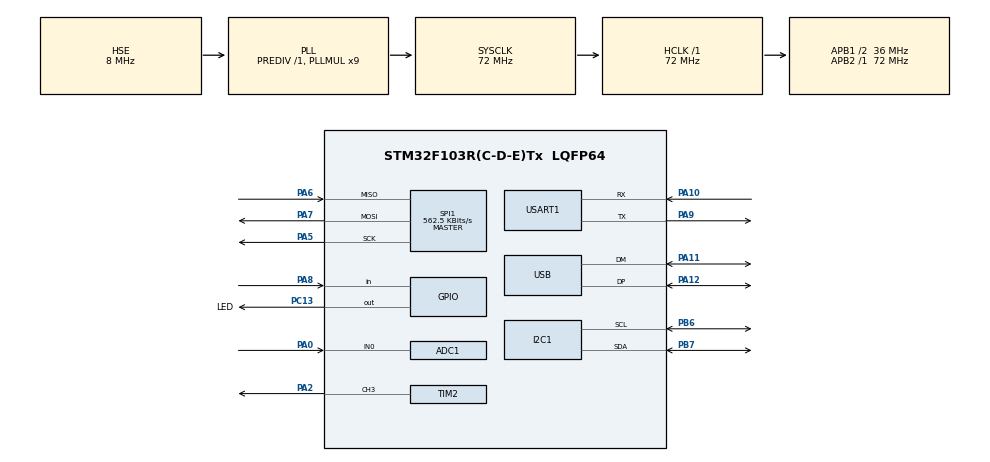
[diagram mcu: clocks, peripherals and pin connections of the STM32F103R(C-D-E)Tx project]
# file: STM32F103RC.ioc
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ADC1.Channel-0\#ChannelRegularConversion=ADC_CHANNEL_0
ADC1.NbrOfConversionFlag=1
ADC1.Rank-0\#ChannelRegularConversion=1
ADC1.SamplingTime-0\#ChannelRegularConversion=ADC_SAMPLETIME_13CYCLES_5
ADC1.master=1
Dma.Request0=USART1_RX
Dma.Request1=USART1_TX
Dma.USART1_RX.0.Direction=DMA_PERIPH_TO_MEMORY
Dma.USART1_RX.0.Instance=DMA1_Channel5
Dma.USART1_RX.0.MemDataAlignment=DMA_MDATAALIGN_BYTE
Dma.USART1_RX.0.MemInc=DMA_MINC_ENABLE
Dma.USART1_RX.0.Mode=DMA_NORMAL
Dma.USART1_RX.0.PeriphDataAlignment=DMA_PDATAALIGN_BYTE
Dma.USART1_RX.0.PeriphInc=DMA_PINC_DISABLE
Dma.USART1_RX.0.Priority=DMA_PRIORITY_LOW
Dma.USART1_TX.1.Direction=DMA_MEMORY_TO_PERIPH
Dma.USART1_TX.1.Instance=DMA1_Channel4
Dma.USART1_TX.1.MemDataAlignment=DMA_MDATAALIGN_BYTE
Dma.USART1_TX.1.MemInc=DMA_MINC_ENABLE
Dma.USART1_TX.1.Mode=DMA_NORMAL
Dma.USART1_TX.1.PeriphDataAlignment=DMA_PDATAALIGN_BYTE
Dma.USART1_TX.1.PeriphInc=DMA_PINC_DISABLE
Dma.USART1_TX.1.Priority=DMA_PRIORITY_LOW
FREERTOS.INCLUDE_vTaskDelayUntil=1
FREERTOS.Tasks01=defaultTask,0,512,StartDefaultTask,Default,NULL,Dynamic,NULL,NULL
FREERTOS.configTOTAL_HEAP_SIZE=8000
FREERTOS.configUSE_COUNTING_SEMAPHORES=1
FREERTOS.configUSE_RECURSIVE_MUTEXES=1
Mcu.Family=STM32F1
Mcu.Name=STM32F103R(C-D-E)Tx
Mcu.Package=LQFP64
NVIC.DMA1_Channel4_IRQn=true\:5\:0\:false\:false\:true\:true\:false\:true\:true
NVIC.DMA1_Channel5_IRQn=true\:5\:0\:false\:false\:true\:true\:false\:true\:true
NVIC.PriorityGroup=NVIC_PRIORITYGROUP_4
NVIC.TIM3_IRQn=true\:0\:0\:false\:false\:true\:false\:false\:true\:true
NVIC.TimeBase=TIM3_IRQn
NVIC.TimeBaseIP=TIM3
NVIC.USART1_IRQn=true\:5\:0\:false\:false\:true\:true\:true\:true\:true
NVIC.USB_HP_CAN1_TX_IRQn=true\:5\:0\:false\:false\:true\:true\:true\:true\:true
NVIC.USB_LP_CAN1_RX0_IRQn=true\:5\:0\:false\:false\:true\:true\:true\:true\:true
PA0-WKUP.Signal=ADCx_IN0
PA10.Mode=Asynchronous
PA10.Signal=USART1_RX
PA11.Mode=Device
PA11.Signal=USB_DM
PA12.Mode=Device
PA12.Signal=USB_DP
PA13.Mode=Serial_Wire
PA13.Signal=SYS_JTMS-SWDIO
PA14.Mode=Serial_Wire
PA14.Signal=SYS_JTCK-SWCLK
PA2.Signal=S_TIM2_CH3
PA5.Mode=Full_Duplex_Master
PA5.Signal=SPI1_SCK
PA6.Mode=Full_Duplex_Master
PA6.Signal=SPI1_MISO
PA7.Mode=Full_Duplex_Master
PA7.Signal=SPI1_MOSI
PA8.GPIO_PuPd=GPIO_PULLUP
PA8.Signal=GPIO_Input
PA9.Mode=Asynchronous
PA9.Signal=USART1_TX
PB6.Mode=I2C
PB6.Signal=I2C1_SCL
PB7.Mode=I2C
PB7.Signal=I2C1_SDA
PC13-TAMPER-RTC.GPIO_Label=LED
PC13-TAMPER-RTC.Signal=GPIO_Output
PD0-OSC_IN.Mode=HSE-External-Oscillator
PD0-OSC_IN.Signal=RCC_OSC_IN
PD1-OSC_OUT.Mode=HSE-External-Oscillator
PD1-OSC_OUT.Signal=RCC_OSC_OUT
ProjectManager.HeapSize=0x200
ProjectManager.StackSize=0x400
ProjectManager.TargetToolchain=CMake
RCC.ADCPresc=RCC_ADCPCLK2_DIV6
RCC.AHBFreq_Value=72000000
RCC.APB1CLKDivider=RCC_HCLK_DIV2
RCC.APB1Freq_Value=36000000
RCC.APB1TimFreq_Value=72000000
RCC.APB2Freq_Value=72000000
RCC.APB2TimFreq_Value=72000000
RCC.HCLKFreq_Value=72000000
RCC.PLLMUL=RCC_PLL_MUL9
RCC.PLLSourceVirtual=RCC_PLLSOURCE_HSE
RCC.SYSCLKFreq_VALUE=72000000
RCC.SYSCLKSource=RCC_SYSCLKSOURCE_PLLCLK
RCC.USBFreq_Value=48000000
RCC.USBPrescaler=RCC_USBCLKSOURCE_PLL_DIV1_5
SH.ADCx_IN0.0=ADC1_IN0,IN0
SH.S_TIM2_CH3.0=TIM2_CH3,PWM Generation3 CH3
SPI1.BaudRatePrescaler=SPI_BAUDRATEPRESCALER_128
SPI1.CalculateBaudRate=562.5 KBits/s
SPI1.Direction=SPI_DIRECTION_2LINES
SPI1.Mode=SPI_MODE_MASTER
SPI1.VirtualType=VM_MASTER
TIM2.Channel-PWM\ Generation3\ CH3=TIM_CHANNEL_3
USART1.VirtualMode=VM_ASYNC
VP_FREERTOS_VS_CMSIS_V1.Mode=CMSIS_V1
VP_SYS_VS_tim3.Mode=TIM3
board=custom

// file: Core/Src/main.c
/* USER CODE BEGIN Header */
/**
  ******************************************************************************
  * @file           : main.c
  * @brief          : Main program body
  ******************************************************************************
  * @attention
  *
  * Copyright (c) 2025 STMicroelectronics.
  * All rights reserved.
  *
  * This software is licensed under terms that can be found in the LICENSE file
  * in the root directory of this software component.
  * If no LICENSE file comes with this software, it is provided AS-IS.
  *
  ******************************************************************************
  */
/* USER CODE END Header */
#include "main.h"
#include "cmsis_os.h"

ADC_HandleTypeDef hadc1;

I2C_HandleTypeDef hi2c1;

SPI_HandleTypeDef hspi1;

TIM_HandleTypeDef htim2;

UART_HandleTypeDef huart1;
DMA_HandleTypeDef hdma_usart1_rx;
DMA_HandleTypeDef hdma_usart1_tx;

PCD_HandleTypeDef hpcd_USB_FS;

osThreadId defaultTaskHandle;

void SystemClock_Config(void);
static void MX_GPIO_Init(void);
static void MX_DMA_Init(void);
static void MX_USART1_UART_Init(void);
static void MX_ADC1_Init(void);
static void MX_I2C1_Init(void);
static void MX_SPI1_Init(void);
static void MX_TIM2_Init(void);
static void MX_USB_PCD_Init(void);
void StartDefaultTask(void const * argument);

/* USER CODE BEGIN 0 */
#include "app_main.h"
/* USER CODE END 0 */

int main(void)
{

  /* MCU Configuration--------------------------------------------------------*/

  /* Reset of all peripherals, Initializes the Flash interface and the Systick. */
  HAL_Init();

  /* Configure the system clock */
  SystemClock_Config();

  /* Initialize all configured peripherals */
  MX_GPIO_Init();
  MX_DMA_Init();
  MX_USART1_UART_Init();
  MX_ADC1_Init();
  MX_I2C1_Init();
  MX_SPI1_Init();
  MX_TIM2_Init();
  MX_USB_PCD_Init();

  /* Create the thread(s) */
  /* definition and creation of defaultTask */
  osThreadDef(defaultTask, StartDefaultTask, osPriorityNormal, 0, 512);
  defaultTaskHandle = osThreadCreate(osThread(defaultTask), NULL);

  /* Start scheduler */
  osKernelStart();

  /* We should never get here as control is now taken by the scheduler */

  /* Infinite loop */
  while (1)
  {

  }
}

void SystemClock_Config(void)
{
  RCC_OscInitTypeDef RCC_OscInitStruct = {0};
  RCC_ClkInitTypeDef RCC_ClkInitStruct = {0};
  RCC_PeriphCLKInitTypeDef PeriphClkInit = {0};

  /** Initializes the RCC Oscillators according to the specified parameters
  * in the RCC_OscInitTypeDef structure.
  */
  RCC_OscInitStruct.OscillatorType = RCC_OSCILLATORTYPE_HSE;
  RCC_OscInitStruct.HSEState = RCC_HSE_ON;
  RCC_OscInitStruct.HSEPredivValue = RCC_HSE_PREDIV_DIV1;
  RCC_OscInitStruct.HSIState = RCC_HSI_ON;
  RCC_OscInitStruct.PLL.PLLState = RCC_PLL_ON;
  RCC_OscInitStruct.PLL.PLLSource = RCC_PLLSOURCE_HSE;
  RCC_OscInitStruct.PLL.PLLMUL = RCC_PLL_MUL9;
  if (HAL_RCC_OscConfig(&RCC_OscInitStruct) != HAL_OK)
  {
    Error_Handler();
  }

  /** Initializes the CPU, AHB and APB buses clocks
  */
  RCC_ClkInitStruct.ClockType = RCC_CLOCKTYPE_HCLK|RCC_CLOCKTYPE_SYSCLK
                              |RCC_CLOCKTYPE_PCLK1|RCC_CLOCKTYPE_PCLK2;
  RCC_ClkInitStruct.SYSCLKSource = RCC_SYSCLKSOURCE_PLLCLK;
  RCC_ClkInitStruct.AHBCLKDivider = RCC_SYSCLK_DIV1;
  RCC_ClkInitStruct.APB1CLKDivider = RCC_HCLK_DIV2;
  RCC_ClkInitStruct.APB2CLKDivider = RCC_HCLK_DIV1;

  if (HAL_RCC_ClockConfig(&RCC_ClkInitStruct, FLASH_LATENCY_2) != HAL_OK)
  {
    Error_Handler();
  }
  PeriphClkInit.PeriphClockSelection = RCC_PERIPHCLK_ADC|RCC_PERIPHCLK_USB;
  PeriphClkInit.AdcClockSelection = RCC_ADCPCLK2_DIV6;
  PeriphClkInit.UsbClockSelection = RCC_USBCLKSOURCE_PLL_DIV1_5;
  if (HAL_RCCEx_PeriphCLKConfig(&PeriphClkInit) != HAL_OK)
  {
    Error_Handler();
  }
}

static void MX_ADC1_Init(void)
{

  ADC_ChannelConfTypeDef sConfig = {0};

  /** Common config
  */
  hadc1.Instance = ADC1;
  hadc1.Init.ScanConvMode = ADC_SCAN_DISABLE;
  hadc1.Init.ContinuousConvMode = DISABLE;
  hadc1.Init.DiscontinuousConvMode = DISABLE;
  hadc1.Init.ExternalTrigConv = ADC_SOFTWARE_START;
  hadc1.Init.DataAlign = ADC_DATAALIGN_RIGHT;
  hadc1.Init.NbrOfConversion = 1;
  if (HAL_ADC_Init(&hadc1) != HAL_OK)
  {
    Error_Handler();
  }

  /** Configure Regular Channel
  */
  sConfig.Channel = ADC_CHANNEL_0;
  sConfig.Rank = ADC_REGULAR_RANK_1;
  sConfig.SamplingTime = ADC_SAMPLETIME_13CYCLES_5;
  if (HAL_ADC_ConfigChannel(&hadc1, &sConfig) != HAL_OK)
  {
    Error_Handler();
  }

}

static void MX_I2C1_Init(void)
{

  hi2c1.Instance = I2C1;
  hi2c1.Init.ClockSpeed = 100000;
  hi2c1.Init.DutyCycle = I2C_DUTYCYCLE_2;
  hi2c1.Init.OwnAddress1 = 0;
  hi2c1.Init.AddressingMode = I2C_ADDRESSINGMODE_7BIT;
  hi2c1.Init.DualAddressMode = I2C_DUALADDRESS_DISABLE;
  hi2c1.Init.OwnAddress2 = 0;
  hi2c1.Init.GeneralCallMode = I2C_GENERALCALL_DISABLE;
  hi2c1.Init.NoStretchMode = I2C_NOSTRETCH_DISABLE;
  if (HAL_I2C_Init(&hi2c1) != HAL_OK)
  {
    Error_Handler();
  }

}

static void MX_SPI1_Init(void)
{

  /* SPI1 parameter configuration*/
  hspi1.Instance = SPI1;
  hspi1.Init.Mode = SPI_MODE_MASTER;
  hspi1.Init.Direction = SPI_DIRECTION_2LINES;
  hspi1.Init.DataSize = SPI_DATASIZE_8BIT;
  hspi1.Init.CLKPolarity = SPI_POLARITY_LOW;
  hspi1.Init.CLKPhase = SPI_PHASE_1EDGE;
  hspi1.Init.NSS = SPI_NSS_SOFT;
  hspi1.Init.BaudRatePrescaler = SPI_BAUDRATEPRESCALER_128;
  hspi1.Init.FirstBit = SPI_FIRSTBIT_MSB;
  hspi1.Init.TIMode = SPI_TIMODE_DISABLE;
  hspi1.Init.CRCCalculation = SPI_CRCCALCULATION_DISABLE;
  hspi1.Init.CRCPolynomial = 10;
  if (HAL_SPI_Init(&hspi1) != HAL_OK)
  {
    Error_Handler();
  }

}

static void MX_TIM2_Init(void)
{

  TIM_MasterConfigTypeDef sMasterConfig = {0};
  TIM_OC_InitTypeDef sConfigOC = {0};

  htim2.Instance = TIM2;
  htim2.Init.Prescaler = 0;
  htim2.Init.CounterMode = TIM_COUNTERMODE_UP;
  htim2.Init.Period = 65535;
  htim2.Init.ClockDivision = TIM_CLOCKDIVISION_DIV1;
  htim2.Init.AutoReloadPreload = TIM_AUTORELOAD_PRELOAD_DISABLE;
  if (HAL_TIM_PWM_Init(&htim2) != HAL_OK)
  {
    Error_Handler();
  }
  sMasterConfig.MasterOutputTrigger = TIM_TRGO_RESET;
  sMasterConfig.MasterSlaveMode = TIM_MASTERSLAVEMODE_DISABLE;
  if (HAL_TIMEx_MasterConfigSynchronization(&htim2, &sMasterConfig) != HAL_OK)
  {
    Error_Handler();
  }
  sConfigOC.OCMode = TIM_OCMODE_PWM1;
  sConfigOC.Pulse = 0;
  sConfigOC.OCPolarity = TIM_OCPOLARITY_HIGH;
  sConfigOC.OCFastMode = TIM_OCFAST_DISABLE;
  if (HAL_TIM_PWM_ConfigChannel(&htim2, &sConfigOC, TIM_CHANNEL_3) != HAL_OK)
  {
    Error_Handler();
  }
  HAL_TIM_MspPostInit(&htim2);

}

static void MX_USART1_UART_Init(void)
{

  huart1.Instance = USART1;
  huart1.Init.BaudRate = 115200;
  huart1.Init.WordLength = UART_WORDLENGTH_8B;
  huart1.Init.StopBits = UART_STOPBITS_1;
  huart1.Init.Parity = UART_PARITY_NONE;
  huart1.Init.Mode = UART_MODE_TX_RX;
  huart1.Init.HwFlowCtl = UART_HWCONTROL_NONE;
  huart1.Init.OverSampling = UART_OVERSAMPLING_16;
  if (HAL_UART_Init(&huart1) != HAL_OK)
  {
    Error_Handler();
  }

}

static void MX_USB_PCD_Init(void)
{

  hpcd_USB_FS.Instance = USB;
  hpcd_USB_FS.Init.dev_endpoints = 8;
  hpcd_USB_FS.Init.speed = PCD_SPEED_FULL;
  hpcd_USB_FS.Init.low_power_enable = DISABLE;
  hpcd_USB_FS.Init.lpm_enable = DISABLE;
  hpcd_USB_FS.Init.battery_charging_enable = DISABLE;
  if (HAL_PCD_Init(&hpcd_USB_FS) != HAL_OK)
  {
    Error_Handler();
  }

}

static void MX_DMA_Init(void)
{

  /* DMA controller clock enable */
  __HAL_RCC_DMA1_CLK_ENABLE();

  /* DMA interrupt init */
  /* DMA1_Channel4_IRQn interrupt configuration */
  HAL_NVIC_SetPriority(DMA1_Channel4_IRQn, 5, 0);
  HAL_NVIC_EnableIRQ(DMA1_Channel4_IRQn);
  /* DMA1_Channel5_IRQn interrupt configuration */
  HAL_NVIC_SetPriority(DMA1_Channel5_IRQn, 5, 0);
  HAL_NVIC_EnableIRQ(DMA1_Channel5_IRQn);

}

static void MX_GPIO_Init(void)
{
  GPIO_InitTypeDef GPIO_InitStruct = {0};

  /* GPIO Ports Clock Enable */
  __HAL_RCC_GPIOC_CLK_ENABLE();
  __HAL_RCC_GPIOD_CLK_ENABLE();
  __HAL_RCC_GPIOA_CLK_ENABLE();
  __HAL_RCC_GPIOB_CLK_ENABLE();

  /*Configure GPIO pin Output Level */
  HAL_GPIO_WritePin(LED_GPIO_Port, LED_Pin, GPIO_PIN_RESET);

  /*Configure GPIO pin : LED_Pin */
  GPIO_InitStruct.Pin = LED_Pin;
  GPIO_InitStruct.Mode = GPIO_MODE_OUTPUT_PP;
  GPIO_InitStruct.Pull = GPIO_NOPULL;
  GPIO_InitStruct.Speed = GPIO_SPEED_FREQ_LOW;
  HAL_GPIO_Init(LED_GPIO_Port, &GPIO_InitStruct);

  /*Configure GPIO pin : PA8 */
  GPIO_InitStruct.Pin = GPIO_PIN_8;
  GPIO_InitStruct.Mode = GPIO_MODE_INPUT;
  GPIO_InitStruct.Pull = GPIO_PULLUP;
  HAL_GPIO_Init(GPIOA, &GPIO_InitStruct);

  /* USER CODE BEGIN MX_GPIO_Init_2 */
  GPIO_InitStruct.Pin = GPIO_PIN_12;
  GPIO_InitStruct.Mode = GPIO_MODE_OUTPUT_PP;
  GPIO_InitStruct.Pull = GPIO_PULLDOWN;
  GPIO_InitStruct.Speed = GPIO_SPEED_FREQ_LOW;
  HAL_GPIO_Init(GPIOA, &GPIO_InitStruct);
  HAL_GPIO_WritePin(GPIOA, GPIO_PIN_12, GPIO_PIN_RESET);
  HAL_Delay(10);
  HAL_GPIO_WritePin(GPIOA,GPIO_PIN_12,GPIO_PIN_SET);
  HAL_Delay(10);
  /* USER CODE END MX_GPIO_Init_2 */
}

void StartDefaultTask(void const * argument)
{
  /* USER CODE BEGIN 5 */
  app_main();
  /* Infinite loop */
  for(;;)
  {
    osDelay(1);
  }
  /* USER CODE END 5 */
}

void HAL_TIM_PeriodElapsedCallback(TIM_HandleTypeDef *htim)
{
  if (htim->Instance == TIM3)
  {
    HAL_IncTick();
  }
}

void Error_Handler(void)
{
  __disable_irq();
  while (1)
  {
  }
}
